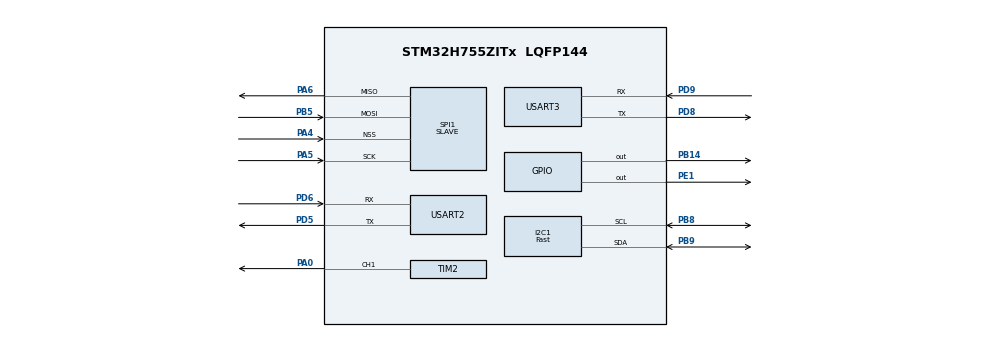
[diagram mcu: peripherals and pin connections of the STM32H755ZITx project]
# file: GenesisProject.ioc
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Mcu.Family=STM32H7
PA6.Mode=Full_Duplex_Slave
RCC.CortexFreq_Value=64000000
I2C1.I2C_Speed_Mode=I2C_Fast
SPI1.VirtualType=VM_SLAVE
RCC.PLLFRACN=3072
PA6.PinAttribute=CortexM7
PA5.PinAttribute=CortexM7
PD9.Mode=Asynchronous
ProjectManager.StackSize=0x400
PB8.PinAttribute=CortexM7
USART3.VirtualMode-Asynchronous=VM_ASYNC
PA4.Mode=NSS_Signal_Hard_Input
SPI1.Direction=SPI_DIRECTION_2LINES
RCC.HCLKFreq_Value=64000000
PD8.Signal=USART3_TX
PE1.Signal=GPIO_Output
PD5.Mode=Asynchronous
USART2.VirtualMode-Asynchronous=VM_ASYNC
RCC.DIVM1=4
NVIC2.PriorityGroup=NVIC_PRIORITYGROUP_4
PD8.PinAttribute=CortexM7
PB5.Mode=Full_Duplex_Slave
SPI1.DataSize=SPI_DATASIZE_8BIT
VP_SYS_M4_VS_Systick.Mode=SysTick
SPI1.VirtualNSS=VM_NSSHARD
TIM2.Channel-PWM\ Generation1\ CH1=TIM_CHANNEL_1
CortexM7.Pins=PB14,PE1
CortexM7.IPs=BDMA\:I,CORTEX_M7\:I,DEBUG\:I,DMA\:I,FATFS_M7\:I,FREERTOS_M7\:I,IWDG1\:I,MDMA\:I,NVIC1\:I,OPENAMP_M7\:I,PDM2PCM_M7\:I,PWR\:I,RCC\:I,RESMGR_UTILITY\:I,SYS\:I,USB_DEVICE_M7\:I,USB_HOST_M7\:I,VREFBUF\:I,WWDG1\:I,USART3\:I,SPI1\:I,I2C1\:I,TIM2\:I,USART2\:I
PA0.Signal=S_TIM2_CH1
RCC.APB3Freq_Value=64000000
PB9.Signal=I2C1_SDA
Mcu.Package=LQFP144
TIM2.Prescaler=4
PA6.Signal=SPI1_MISO
RCC.APB4Freq_Value=64000000
SPI1.IOSwap=SPI_IO_SWAP_DISABLE
PD6.Signal=USART2_RX
PA5.Mode=Full_Duplex_Slave
PB14.PinAttribute=CortexM7
SH.S_TIM2_CH1.0=TIM2_CH1,PWM Generation1 CH1
PD6.PinAttribute=CortexM7
NVIC1.PriorityGroup=NVIC_PRIORITYGROUP_4
RCC.D2PPRE1=RCC_APB1_DIV2
PD9.Signal=USART3_RX
PD5.Signal=USART2_TX
PD6.Mode=Asynchronous
NVIC1.SPI1_IRQn=true\:0\:0\:false\:false\:true\:true\:true
SYS.userName=SYS_M7
PA0.PinAttribute=CortexM7
ProjectManager.TargetToolchain=STM32CubeIDE
PB9.Mode=I2C
I2C1.Timing=0x00300F38
RCC.DIVN1=9
RCC.USBFreq_Value=75000000
PD8.Mode=Asynchronous
PB14.Signal=GPIO_Output
PA5.Signal=SPI1_SCK
board=custom
NVIC1.USART2_IRQn=true\:0\:0\:false\:false\:true\:true\:true
PB9.PinAttribute=CortexM7
PB5.PinAttribute=CortexM7
RCC.APB2Freq_Value=64000000
VP_TIM2_VS_ClockSourceINT.Mode=Internal
SPI1.Mode=SPI_MODE_SLAVE
RCC.ADCFreq_Value=129000000
TIM2.Period=320000
PE1.PinAttribute=CortexM7
Mcu.Name=STM32H755ZITx
PA4.PinAttribute=CortexM7
PA4.Signal=SPI1_NSS
RCC.SYSCLKFreq_VALUE=64000000
PB5.Signal=SPI1_MOSI
ProjectManager.HeapSize=0x200
PD9.PinAttribute=CortexM7
PD5.PinAttribute=CortexM7
PB8.Mode=I2C
PB8.Signal=I2C1_SCL
RCC.APB1Freq_Value=32000000
CortexM4.IPs=BDMA,CORTEX_M4\:I,DEBUG,DMA,FATFS_M4\:I,FREERTOS_M4\:I,IWDG2\:I,MDMA,NVIC2\:I,OPENAMP_M4\:I,PDM2PCM_M4\:I,PWR,RCC,RESMGR_UTILITY,SYS_M4\:I,USB_DEVICE_M4\:I,USB_HOST_M4\:I,VREFBUF,WWDG2\:I

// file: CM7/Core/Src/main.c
/* USER CODE BEGIN Header */
/**
  ******************************************************************************
  * @file           : main.c
  * @brief          : Main program body
  ******************************************************************************
  * @attention
  *
  * <h2><center>&copy; Copyright (c) 2024 STMicroelectronics.
  * All rights reserved.</center></h2>
  *
  * This software component is licensed by ST under BSD 3-Clause license,
  * the "License"; You may not use this file except in compliance with the
  * License. You may obtain a copy of the License at:
  *                        opensource.org/licenses/BSD-3-Clause
  *
  ******************************************************************************
  */
/* USER CODE END Header */
#include "main.h"
#include "i2c.h"
#include "spi.h"
#include "tim.h"
#include "usart.h"
#include "gpio.h"

/* USER CODE BEGIN Includes */

#include "AppMainCM7.h"

/* USER CODE END Includes */

/* USER CODE BEGIN PD */

#ifndef HSEM_ID_0
#define HSEM_ID_0 (0U) /* HW semaphore 0*/
#endif
/* USER CODE END PD */

void SystemClock_Config(void);

int main(void)
{
/* USER CODE BEGIN Boot_Mode_Sequence_0 */
  int32_t timeout;
/* USER CODE END Boot_Mode_Sequence_0 */

/* USER CODE BEGIN Boot_Mode_Sequence_1 */
  /* Wait until CPU2 boots and enters in stop mode or timeout*/
  // timeout = 0xFFFF;
  // while((__HAL_RCC_GET_FLAG(RCC_FLAG_D2CKRDY) != RESET) && (timeout-- > 0));
  // if ( timeout < 0 )
  // {
  // Error_Handler();
  // }
/* USER CODE END Boot_Mode_Sequence_1 */
  /* MCU Configuration--------------------------------------------------------*/

  /* Reset of all peripherals, Initializes the Flash interface and the Systick. */
  HAL_Init();

  /* Configure the system clock */
  SystemClock_Config();
/* USER CODE BEGIN Boot_Mode_Sequence_2 */
/* When system initialization is finished, Cortex-M7 will release Cortex-M4 by means of
HSEM notification */
/*HW semaphore Clock enable*/
__HAL_RCC_HSEM_CLK_ENABLE();
/*Take HSEM */
// HAL_HSEM_FastTake(HSEM_ID_0);
// /*Release HSEM in order to notify the CPU2(CM4)*/
// HAL_HSEM_Release(HSEM_ID_0,0);
// /* wait until CPU2 wakes up from stop mode */
// timeout = 0xFFFF;
// while((__HAL_RCC_GET_FLAG(RCC_FLAG_D2CKRDY) == RESET) && (timeout-- > 0));
// if ( timeout < 0 )
// {
// Error_Handler();
// }
/* USER CODE END Boot_Mode_Sequence_2 */

  /* Initialize all configured peripherals */
  MX_GPIO_Init();
  MX_I2C1_Init();
  MX_SPI1_Init();
  MX_USART3_UART_Init();
  MX_TIM2_Init();
  MX_USART2_UART_Init();
  /* USER CODE BEGIN 2 */

  AppCM7_Main();
  TIM2->CCR1 = 24000;
  HAL_TIM_PWM_Start(&htim2, TIM_CHANNEL_1);
  /* USER CODE END 2 */

  /* Infinite loop */
  while (1)
  {

  }
}

void SystemClock_Config(void)
{
  RCC_OscInitTypeDef RCC_OscInitStruct = {0};
  RCC_ClkInitTypeDef RCC_ClkInitStruct = {0};

  /** Supply configuration update enable
  */
  HAL_PWREx_ConfigSupply(PWR_DIRECT_SMPS_SUPPLY);
  /** Configure the main internal regulator output voltage
  */
  __HAL_PWR_VOLTAGESCALING_CONFIG(PWR_REGULATOR_VOLTAGE_SCALE3);

  while(!__HAL_PWR_GET_FLAG(PWR_FLAG_VOSRDY)) {}
  /** Initializes the RCC Oscillators according to the specified parameters
  * in the RCC_OscInitTypeDef structure.
  */
  RCC_OscInitStruct.OscillatorType = RCC_OSCILLATORTYPE_HSI;
  RCC_OscInitStruct.HSIState = RCC_HSI_DIV1;
  RCC_OscInitStruct.HSICalibrationValue = RCC_HSICALIBRATION_DEFAULT;
  RCC_OscInitStruct.PLL.PLLState = RCC_PLL_ON;
  RCC_OscInitStruct.PLL.PLLSource = RCC_PLLSOURCE_HSI;
  RCC_OscInitStruct.PLL.PLLM = 4;
  RCC_OscInitStruct.PLL.PLLN = 9;
  RCC_OscInitStruct.PLL.PLLP = 2;
  RCC_OscInitStruct.PLL.PLLQ = 2;
  RCC_OscInitStruct.PLL.PLLR = 2;
  RCC_OscInitStruct.PLL.PLLRGE = RCC_PLL1VCIRANGE_3;
  RCC_OscInitStruct.PLL.PLLVCOSEL = RCC_PLL1VCOMEDIUM;
  RCC_OscInitStruct.PLL.PLLFRACN = 3072;
  if (HAL_RCC_OscConfig(&RCC_OscInitStruct) != HAL_OK)
  {
    Error_Handler();
  }
  /** Initializes the CPU, AHB and APB buses clocks
  */
  RCC_ClkInitStruct.ClockType = RCC_CLOCKTYPE_HCLK|RCC_CLOCKTYPE_SYSCLK
                              |RCC_CLOCKTYPE_PCLK1|RCC_CLOCKTYPE_PCLK2
                              |RCC_CLOCKTYPE_D3PCLK1|RCC_CLOCKTYPE_D1PCLK1;
  RCC_ClkInitStruct.SYSCLKSource = RCC_SYSCLKSOURCE_HSI;
  RCC_ClkInitStruct.SYSCLKDivider = RCC_SYSCLK_DIV1;
  RCC_ClkInitStruct.AHBCLKDivider = RCC_HCLK_DIV1;
  RCC_ClkInitStruct.APB3CLKDivider = RCC_APB3_DIV1;
  RCC_ClkInitStruct.APB1CLKDivider = RCC_APB1_DIV2;
  RCC_ClkInitStruct.APB2CLKDivider = RCC_APB2_DIV1;
  RCC_ClkInitStruct.APB4CLKDivider = RCC_APB4_DIV1;

  if (HAL_RCC_ClockConfig(&RCC_ClkInitStruct, FLASH_LATENCY_1) != HAL_OK)
  {
    Error_Handler();
  }
}

void Error_Handler(void)
{
  __disable_irq();
  while (1)
  {
  }
}

/************************ (C) COPYRIGHT STMicroelectronics *****END OF FILE****/
